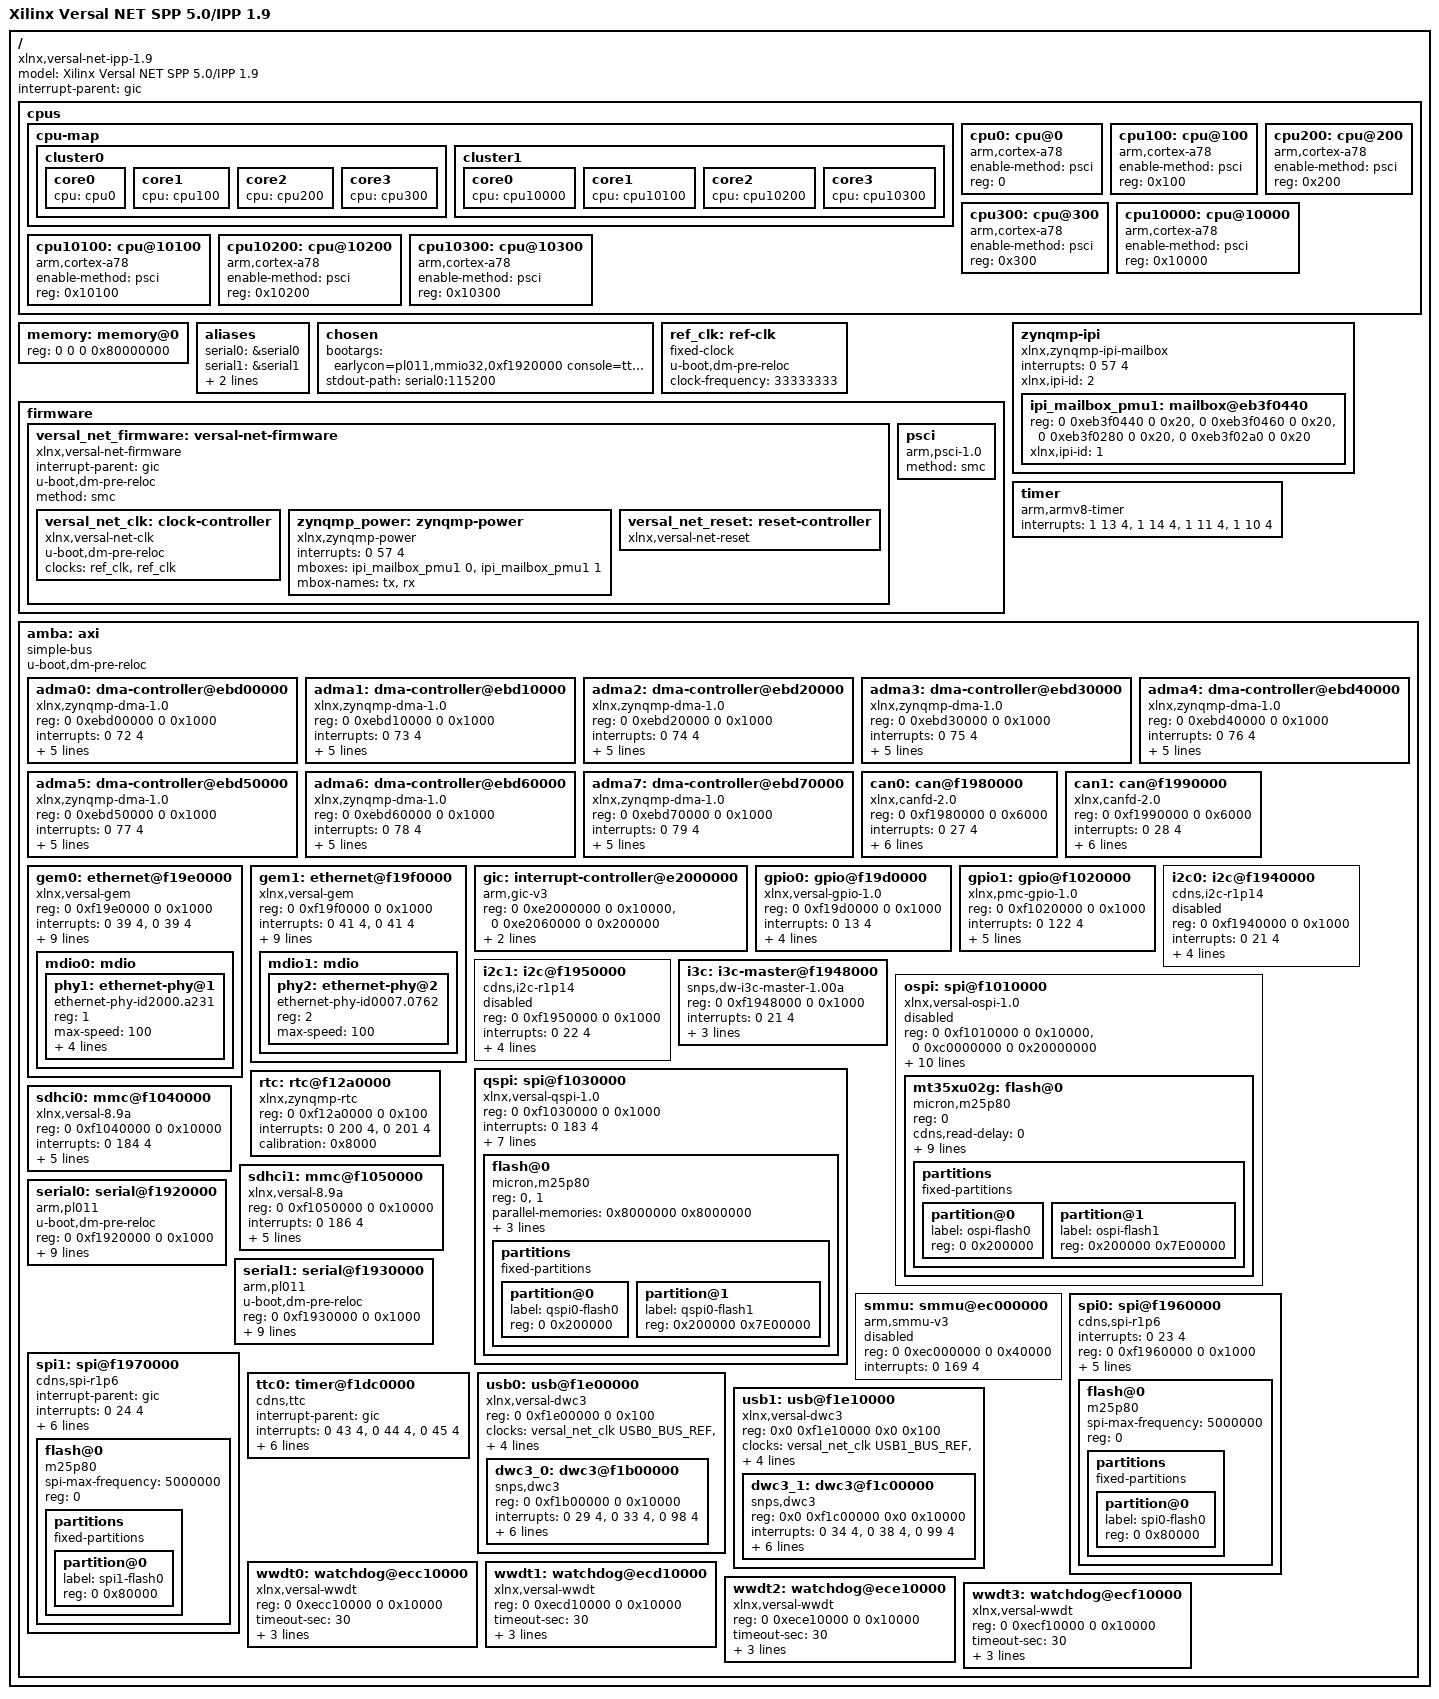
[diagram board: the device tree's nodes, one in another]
// SPDX-License-Identifier: GPL-2.0
/*
 * dts file for Xilinx Versal NET
 *
 * (C) Copyright 2021 - 2022, Xilinx, Inc.
 *
 * Michal Simek <michal.simek@amd.com>
 */

/dts-v1/;

#include <dt-bindings/gpio/gpio.h>
#include <dt-bindings/clock/xlnx-versal-net-clk.h>
#include <dt-bindings/power/xlnx-versal-net-power.h>
#include <dt-bindings/reset/xlnx-versal-net-resets.h>

/ {
	compatible = "xlnx,versal-net-ipp-1.9", "xlnx,versal-net-spp-5.0", "xlnx,versal-net-spp", "xlnx,versal-net";
	model = "Xilinx Versal NET SPP 5.0/IPP 1.9";
	#address-cells = <2>;
	#size-cells = <2>;
	interrupt-parent = <&gic>;

	cpus {
		#address-cells = <1>;
		#size-cells = <0>;
		cpu-map {
			cluster0 {
				core0 {
					cpu = <&cpu0>;
				};
				core1 {
					cpu = <&cpu100>;
				};
				core2 {
					cpu = <&cpu200>;
				};
				core3 {
					cpu = <&cpu300>;
				};
			};

			cluster1 {
				core0 {
					cpu = <&cpu10000>;
				};

				core1 {
					cpu = <&cpu10100>;
				};

				core2 {
					cpu = <&cpu10200>;
				};

				core3 {
					cpu = <&cpu10300>;
				};
			};
		};

		cpu0: cpu@0 {
			compatible = "arm,cortex-a78";
			device_type = "cpu";
			enable-method = "psci";
			reg = <0>;
		};
		cpu100: cpu@100 {
			compatible = "arm,cortex-a78";
			device_type = "cpu";
			enable-method = "psci";
			reg = <0x100>;
		};
		cpu200: cpu@200 {
			compatible = "arm,cortex-a78";
			device_type = "cpu";
			enable-method = "psci";
			reg = <0x200>;
		};
		cpu300: cpu@300 {
			compatible = "arm,cortex-a78";
			device_type = "cpu";
			enable-method = "psci";
			reg = <0x300>;
		};
		cpu10000: cpu@10000 {
			compatible = "arm,cortex-a78";
			device_type = "cpu";
			enable-method = "psci";
			reg = <0x10000>;
		};
		cpu10100: cpu@10100 {
			compatible = "arm,cortex-a78";
			device_type = "cpu";
			enable-method = "psci";
			reg = <0x10100>;
		};
		cpu10200: cpu@10200 {
			compatible = "arm,cortex-a78";
			device_type = "cpu";
			enable-method = "psci";
			reg = <0x10200>;
		};
		cpu10300: cpu@10300 {
			compatible = "arm,cortex-a78";
			device_type = "cpu";
			enable-method = "psci";
			reg = <0x10300>;
		};
	};

	memory: memory@0 {
		reg = <0 0 0 0x80000000>;
		device_type = "memory";
	};

	aliases {
		serial0 = &serial0;
		serial1 = &serial1;
		mmc0 = &sdhci0;
		mmc1 = &sdhci1;
	};

	chosen {
		bootargs = "earlycon=pl011,mmio32,0xf1920000 console=ttyAMA0,115200 spi-cadence-quadspi.read_timeout_ms=30 dw-i3c-master.scl_timing_quirk_spp=1";
		stdout-path = "serial0:115200";
	};

	ref_clk: ref-clk {
		compatible = "fixed-clock";
		u-boot,dm-pre-reloc;
		#clock-cells = <0>;
		clock-frequency = <33333333>;
	};

	firmware {
		versal_net_firmware: versal-net-firmware {
			compatible = "xlnx,versal-net-firmware";
			interrupt-parent = <&gic>;
			u-boot,dm-pre-reloc;
			method = "smc";
			#power-domain-cells = <0x01>;

			versal_net_clk: clock-controller {
				u-boot,dm-pre-reloc;
				#clock-cells = <1>;
				compatible = "xlnx,versal-net-clk";
				clocks = <&ref_clk>, <&ref_clk>;
				clock-names = "ref_clk", "pl_alt_ref_clk";
			};

			zynqmp_power: zynqmp-power {
				compatible = "xlnx,zynqmp-power";
				interrupts = <0 57 4>;
				mboxes = <&ipi_mailbox_pmu1 0>,
					<&ipi_mailbox_pmu1 1>;
				mbox-names = "tx", "rx";
			};

			versal_net_reset: reset-controller {
				compatible = "xlnx,versal-net-reset";
				#reset-cells = <1>;
			};
		};

		psci {
			compatible = "arm,psci-1.0";
			method = "smc";
		};
	};

	zynqmp-ipi {
		compatible = "xlnx,zynqmp-ipi-mailbox";
		interrupts = <0 57 4>;
		xlnx,ipi-id = <2>;
		#address-cells = <2>;
		#size-cells = <2>;
		ranges;

		ipi_mailbox_pmu1: mailbox@eb3f0440 {
			reg = <0 0xeb3f0440 0 0x20>,
			      <0 0xeb3f0460 0 0x20>,
			      <0 0xeb3f0280 0 0x20>,
			      <0 0xeb3f02a0 0 0x20>;
			reg-names = "local_request_region", "local_response_region",
				    "remote_request_region", "remote_response_region";
			#mbox-cells = <1>;
			xlnx,ipi-id = <1>;
		};
	};

	timer: timer {
		compatible = "arm,armv8-timer";
		interrupts = <1 13 4>, <1 14 4>, <1 11 4>, <1 10 4>; /* FIXME 3rd cell */
	};

	amba: axi {
		compatible = "simple-bus";
		u-boot,dm-pre-reloc;
		#address-cells = <2>;
		#size-cells = <2>;
		ranges;

		adma0: dma-controller@ebd00000 {
			compatible = "xlnx,zynqmp-dma-1.0";
			status = "okay";
			reg = <0 0xebd00000 0 0x1000>;
			interrupts = <0 72 4>;
			clock-names = "clk_main", "clk_apb";
			#dma-cells = <1>;
			xlnx,bus-width = <64>;
			clocks = <&versal_net_clk ADMA>, <&versal_net_clk LPD_LSBUS>;
			power-domains = <&versal_net_firmware PM_DEV_ADMA_0>;
		};

		adma1: dma-controller@ebd10000 {
			compatible = "xlnx,zynqmp-dma-1.0";
			status = "okay";
			reg = <0 0xebd10000 0 0x1000>;
			interrupts = <0 73 4>;
			clock-names = "clk_main", "clk_apb";
			#dma-cells = <1>;
			xlnx,bus-width = <64>;
			clocks = <&versal_net_clk ADMA>, <&versal_net_clk LPD_LSBUS>;
			power-domains = <&versal_net_firmware PM_DEV_ADMA_1>;
		};

		adma2: dma-controller@ebd20000 {
			compatible = "xlnx,zynqmp-dma-1.0";
			status = "okay";
			reg = <0 0xebd20000 0 0x1000>;
			interrupts = <0 74 4>;
			clock-names = "clk_main", "clk_apb";
			#dma-cells = <1>;
			xlnx,bus-width = <64>;
			clocks = <&versal_net_clk ADMA>, <&versal_net_clk LPD_LSBUS>;
			power-domains = <&versal_net_firmware PM_DEV_ADMA_2>;
		};

		adma3: dma-controller@ebd30000 {
			compatible = "xlnx,zynqmp-dma-1.0";
			status = "okay";
			reg = <0 0xebd30000 0 0x1000>;
			interrupts = <0 75 4>;
			clock-names = "clk_main", "clk_apb";
			#dma-cells = <1>;
			xlnx,bus-width = <64>;
			clocks = <&versal_net_clk ADMA>, <&versal_net_clk LPD_LSBUS>;
			power-domains = <&versal_net_firmware PM_DEV_ADMA_3>;
		};

		adma4: dma-controller@ebd40000 {
			compatible = "xlnx,zynqmp-dma-1.0";
			status = "okay";
			reg = <0 0xebd40000 0 0x1000>;
			interrupts = <0 76 4>;
			clock-names = "clk_main", "clk_apb";
			#dma-cells = <1>;
			xlnx,bus-width = <64>;
			clocks = <&versal_net_clk ADMA>, <&versal_net_clk LPD_LSBUS>;
			power-domains = <&versal_net_firmware PM_DEV_ADMA_4>;
		};

		adma5: dma-controller@ebd50000 {
			compatible = "xlnx,zynqmp-dma-1.0";
			status = "okay";
			reg = <0 0xebd50000 0 0x1000>;
			interrupts = <0 77 4>;
			clock-names = "clk_main", "clk_apb";
			#dma-cells = <1>;
			xlnx,bus-width = <64>;
			clocks = <&versal_net_clk ADMA>, <&versal_net_clk LPD_LSBUS>;
			power-domains = <&versal_net_firmware PM_DEV_ADMA_5>;
		};

		adma6: dma-controller@ebd60000 {
			compatible = "xlnx,zynqmp-dma-1.0";
			status = "okay";
			reg = <0 0xebd60000 0 0x1000>;
			interrupts = <0 78 4>;
			clock-names = "clk_main", "clk_apb";
			#dma-cells = <1>;
			xlnx,bus-width = <64>;
			clocks = <&versal_net_clk ADMA>, <&versal_net_clk LPD_LSBUS>;
			power-domains = <&versal_net_firmware PM_DEV_ADMA_6>;
		};

		adma7: dma-controller@ebd70000 {
			compatible = "xlnx,zynqmp-dma-1.0";
			status = "okay";
			reg = <0 0xebd70000 0 0x1000>;
			interrupts = <0 79 4>;
			clock-names = "clk_main", "clk_apb";
			#dma-cells = <1>;
			xlnx,bus-width = <64>;
			clocks = <&versal_net_clk ADMA>, <&versal_net_clk LPD_LSBUS>;
			power-domains = <&versal_net_firmware PM_DEV_ADMA_7>;
		};

		can0: can@f1980000 {
			compatible = "xlnx,canfd-2.0";
			status = "okay";
			reg = <0 0xf1980000 0 0x6000>;
			interrupts = <0 27 4>;
			clock-names = "can_clk", "s_axi_aclk";
			rx-fifo-depth = <64>;
			tx-mailbox-count = <32>;
			clocks = <&versal_net_clk CAN0_REF_2X>, <&versal_net_clk LPD_LSBUS>;
			power-domains = <&versal_net_firmware PM_DEV_CAN_FD_0>;
		};

		can1: can@f1990000 {
			compatible = "xlnx,canfd-2.0";
			status = "okay";
			reg = <0 0xf1990000 0 0x6000>;
			interrupts = <0 28 4>;
			clock-names = "can_clk", "s_axi_aclk";
			rx-fifo-depth = <64>;
			tx-mailbox-count = <32>;
			clocks = <&versal_net_clk CAN1_REF_2X>, <&versal_net_clk LPD_LSBUS>;
			power-domains = <&versal_net_firmware PM_DEV_CAN_FD_1>;
		};

		gem0: ethernet@f19e0000 {
			compatible = "xlnx,versal-gem", "cdns,gem";
			status = "okay";
			reg = <0 0xf19e0000 0 0x1000>;
			interrupts = <0 39 4>, <0 39 4>;
			clock-names = "pclk", "hclk", "tx_clk", "rx_clk", "tsu_clk";
			#address-cells = <1>;
			#size-cells = <0>;
			phy-handle = <&phy1>;
			phy-mode = "rgmii-id";
			clocks = <&versal_net_clk LPD_LSBUS>,
				 <&versal_net_clk GEM0_REF>, <&versal_net_clk GEM0_TX>,
				 <&versal_net_clk GEM0_RX>, <&versal_net_clk GEM_TSU>;
			power-domains = <&versal_net_firmware PM_DEV_GEM_0>;
			mdio0: mdio {
				#address-cells = <1>;
				#size-cells = <0>;
				phy1: ethernet-phy@1 {
					#phy-cells = <1>;
					compatible = "ethernet-phy-id2000.a231";
					reg = <1>;
					max-speed = <100>;
					ti,rx-internal-delay = <11>;
					ti,tx-internal-delay = <10>;
					ti,fifo-depth = <1>;
					ti,dp83867-rxctrl-strap-quirk;
				};
			};
		};

		gem1: ethernet@f19f0000 {
			compatible = "xlnx,versal-gem", "cdns,gem";
			status = "okay";
			reg = <0 0xf19f0000 0 0x1000>;
			interrupts = <0 41 4>, <0 41 4>;
			clock-names = "pclk", "hclk", "tx_clk", "rx_clk", "tsu_clk";
			#address-cells = <1>;
			#size-cells = <0>;
			phy-handle = <&phy2>;
			phy-mode = "rmii";
			clocks = <&versal_net_clk LPD_LSBUS>,
				 <&versal_net_clk GEM1_REF>, <&versal_net_clk GEM1_TX>,
				 <&versal_net_clk GEM1_RX>, <&versal_net_clk GEM_TSU>;
			power-domains = <&versal_net_firmware PM_DEV_GEM_1>;
			mdio1: mdio {
				#address-cells = <1>;
				#size-cells = <0>;

				phy2: ethernet-phy@2 {
					compatible = "ethernet-phy-id0007.0762"; /* Vitesse VSC8540 */
					reg = <2>;
					max-speed = <100>;
				};
			};
		};

		gic: interrupt-controller@e2000000 {
			compatible = "arm,gic-v3";
			#interrupt-cells = <3>;
			reg = <0 0xe2000000 0 0x10000>, <0 0xe2060000 0 0x200000>;
			interrupt-controller;
			interrupts = <1 9 4>;
		};

		gpio0: gpio@f19d0000 {
			compatible = "xlnx,versal-gpio-1.0";
			status = "okay";
			reg = <0 0xf19d0000 0 0x1000>;
			interrupts = <0 13 4>;
			#gpio-cells = <2>;
			gpio-controller;
			#interrupt-cells = <2>;
			interrupt-controller;
			clocks = <&versal_net_clk LPD_LSBUS>;
			power-domains = <&versal_net_firmware PM_DEV_GPIO>;
		};

		gpio1: gpio@f1020000 {
			compatible = "xlnx,pmc-gpio-1.0";
			status = "okay";
			reg = <0 0xf1020000 0 0x1000>;
			interrupts = <0 122 4>;
			#gpio-cells = <2>;
			gpio-controller;
			#interrupt-cells = <2>;
			interrupt-controller;
			clocks = <&versal_net_clk PMC_LSBUS_REF>;
			power-domains = <&versal_net_firmware PM_DEV_GPIO_PMC>;
		};

		i2c0: i2c@f1940000 {
			compatible = "cdns,i2c-r1p14";
			status = "disabled";
			reg = <0 0xf1940000 0 0x1000>;
			interrupts = <0 21 4>;
			clock-frequency = <400000>;
			#address-cells = <1>;
			#size-cells = <0>;
			clocks = <&versal_net_clk I3C0_REF>;
			power-domains = <&versal_net_firmware PM_DEV_I2C_0>;
		};

		i2c1: i2c@f1950000 {
			compatible = "cdns,i2c-r1p14";
			status = "disabled";
			reg = <0 0xf1950000 0 0x1000>;
			interrupts = <0 22 4>;
			clock-frequency = <400000>;
			#address-cells = <1>;
			#size-cells = <0>;
			clocks = <&versal_net_clk I3C1_REF>;
			power-domains = <&versal_net_firmware PM_DEV_I2C_1>;
		};

		i3c: i3c-master@f1948000 {
			compatible = "snps,dw-i3c-master-1.00a";
			status = "okay";
			reg = <0 0xf1948000 0 0x1000>;
			#address-cells = <1>;
			#size-cells = <0>;
			interrupts = <0 21 4>;
			clocks = <&versal_net_clk I2C_REF>;
			power-domains = <&versal_net_firmware PM_DEV_I2C_PMC>;
		};

		ospi: spi@f1010000 {
			compatible = "xlnx,versal-ospi-1.0", "cdns,qspi-nor";
			status = "disabled";
			reg = <0 0xf1010000 0 0x10000>, <0 0xc0000000 0 0x20000000>;
			interrupts = <0 182 4>;
			cdns,fifo-depth = <256>;
			cdns,fifo-width = <4>;
			cdns,is-dma = <1>;
			cdns,trigger-address = <0xc0000000>;
			is-dual = <0>;
			is-stacked = <0>;
			clocks = <&versal_net_clk OSPI_REF>;
			#address-cells = <1>;
			#size-cells = <0>;
			power-domains = <&versal_net_firmware PM_DEV_OSPI>;
			reset-gpios = <&gpio1 0xc GPIO_ACTIVE_HIGH>;

			mt35xu02g: flash@0 {
				compatible = "micron,m25p80", "jedec,spi-nor";
				reg = <0>;
				#address-cells = <1>;
				#size-cells = <1>;
				cdns,read-delay = <0>;
				cdns,tshsl-ns = <0>;
				cdns,tsd2d-ns = <0>;
				cdns,tchsh-ns = <1>;
				cdns,tslch-ns = <1>;
				spi-tx-bus-width = <8>;
				spi-rx-bus-width = <8>;
				spi-max-frequency = <5000000>;
				broken-flash-reset;
				no-wp;

				partitions {
					compatible = "fixed-partitions";
					#address-cells = <1>;
					#size-cells = <1>;

					partition@0 {
						label = "ospi-flash0";
						reg = <0 0x200000>;
					};
					partition@1 {
						label = "ospi-flash1";
						reg = <0x200000 0x7E00000>;
					};
				};
			};
		};

		qspi: spi@f1030000 {
			compatible = "xlnx,versal-qspi-1.0";
			status = "okay";
			reg = <0 0xf1030000 0 0x1000>;
			interrupts = <0 183 4>;
			clock-names = "ref_clk", "pclk";
			num-cs = <2>;
			is-dual = <1>;
			spi-rx-bus-width = <4>;
			spi-tx-bus-width = <4>;
			clocks = <&versal_net_clk QSPI_REF>, <&versal_net_clk LPD_LSBUS>;
			power-domains = <&versal_net_firmware PM_DEV_QSPI>;
			#address-cells = <1>;
			#size-cells = <0>;

			flash@0 {
				compatible = "micron,m25p80", "jedec,spi-nor";
				reg = <0>, <1>;
				parallel-memories = /bits/ 64 <0x8000000 0x8000000>; /* 128MB */
				#address-cells = <1>;
				#size-cells = <1>;
				spi-tx-bus-width = <1>;
				spi-rx-bus-width = <4>;
				spi-max-frequency = <10000000>;

				partitions {
					compatible = "fixed-partitions";
					#address-cells = <1>;
					#size-cells = <1>;

					partition@0 {
						label = "qspi0-flash0";
						reg = <0 0x200000>;
					};
					partition@1 {
						label = "qspi0-flash1";
						reg = <0x200000 0x7E00000>;
					};
				};
			};
		};

		rtc: rtc@f12a0000 {
			compatible = "xlnx,zynqmp-rtc";
			status = "okay";
			reg = <0 0xf12a0000 0 0x100>;
			interrupts = <0 200 4>, <0 201 4>;
			interrupt-names = "alarm", "sec";
			calibration = <0x8000>;
		};

		sdhci0: mmc@f1040000 {
			compatible = "xlnx,versal-8.9a", "arasan,sdhci-8.9a";
			status = "okay";
			reg = <0 0xf1040000 0 0x10000>;
			interrupts = <0 184 4>;
			clock-names = "clk_xin", "clk_ahb";
			no-1-8-v;
			clocks = <&versal_net_clk SDIO0_REF>, <&versal_net_clk LPD_LSBUS>;
			power-domains = <&versal_net_firmware PM_DEV_SDIO_0>;
		};

		sdhci1: mmc@f1050000 {
			compatible = "xlnx,versal-8.9a", "arasan,sdhci-8.9a";
			status = "okay";
			reg = <0 0xf1050000 0 0x10000>;
			interrupts = <0 186 4>;
			clock-names = "clk_xin", "clk_ahb";
			no-1-8-v;
			clocks = <&versal_net_clk SDIO1_REF>, <&versal_net_clk LPD_LSBUS>;
			power-domains = <&versal_net_firmware PM_DEV_SDIO_1>;
		};

		serial0: serial@f1920000 {
			u-boot,dm-pre-reloc;
			compatible = "arm,pl011", "arm,primecell";
			reg = <0 0xf1920000 0 0x1000>;
			interrupts = <0 25 4>;
			reg-io-width = <4>;
			clock-names = "uartclk", "apb_pclk";
			clocks = <&versal_net_clk UART0_REF>, <&versal_net_clk LPD_LSBUS>;
			power-domains = <&versal_net_firmware PM_DEV_UART_0>;
			clock = <1000000>;
			current-speed = <115200>;
			skip-init;
		};

		serial1: serial@f1930000 {
			u-boot,dm-pre-reloc;
			compatible = "arm,pl011", "arm,primecell";
			reg = <0 0xf1930000 0 0x1000>;
			interrupts = <0 26 4>;
			reg-io-width = <4>;
			clock-names = "uartclk", "apb_pclk";
			clocks = <&versal_net_clk UART1_REF>, <&versal_net_clk LPD_LSBUS>;
			power-domains = <&versal_net_firmware PM_DEV_UART_1>;
			clock = <1000000>;
			current-speed = <115200>;
			skip-init;
		};

		smmu: smmu@ec000000 {
			compatible = "arm,smmu-v3";
			status = "disabled";
			reg = <0 0xec000000 0 0x40000>;
			#iommu-cells = <1>;
			interrupt-names = "combined";
			interrupts = <0 169 4>;
		};

		spi0: spi@f1960000 {
			compatible = "cdns,spi-r1p6";
			status = "okay";
			interrupts = <0 23 4>;
			reg = <0 0xf1960000 0 0x1000>;
			clock-names = "ref_clk", "pclk";
			#address-cells = <1>;
			#size-cells = <0>;
			clocks = <&versal_net_clk SPI0_REF>, <&versal_net_clk LPD_LSBUS>;
			power-domains = <&versal_net_firmware PM_DEV_SPI_0>;
			num-cs = <1>;

			flash@0 {
				compatible = "m25p80";
				spi-max-frequency = <5000000>;
				reg = <0>;

				partitions {
					compatible = "fixed-partitions";
					#address-cells = <1>;
					#size-cells = <1>;
					partition@0 {
						label = "spi0-flash0";
						reg = <0 0x80000>;
					};
				};
			};
		};

		spi1: spi@f1970000 {
			compatible = "cdns,spi-r1p6";
			status = "okay";
			interrupt-parent = <&gic>;
			interrupts = <0 24 4>;
			reg = <0 0xf1970000 0 0x1000>;
			clock-names = "ref_clk", "pclk";
			#address-cells = <1>;
			#size-cells = <0>;
			clocks = <&versal_net_clk SPI1_REF>, <&versal_net_clk LPD_LSBUS>;
			power-domains = <&versal_net_firmware PM_DEV_SPI_1>;
			num-cs = <1>;

			flash@0 {
				compatible = "m25p80";
				spi-max-frequency = <5000000>;
				reg = <0>;

				partitions {
					compatible = "fixed-partitions";
					#address-cells = <1>;
					#size-cells = <1>;
					partition@0 {
						label = "spi1-flash0";
						reg = <0 0x80000>;
					};
				};
			};
		};

		ttc0: timer@f1dc0000 {
			compatible = "cdns,ttc";
			status = "okay";
			interrupt-parent = <&gic>;
			interrupts = <0 43 4>, <0 44 4>, <0 45 4>;
			timer-width = <32>;
			reg = <0x0 0xf1dc0000 0x0 0x1000>;
			clocks = <&versal_net_clk TTC0>, <&versal_net_clk LPD_LSBUS>;
			power-domains = <&versal_net_firmware PM_DEV_TTC_0>;
		};

		usb0: usb@f1e00000 {
			compatible = "xlnx,versal-dwc3";
			status = "okay";
			reg = <0 0xf1e00000 0 0x100>;
			clock-names = "bus_clk", "ref_clk";
			ranges;
			#address-cells = <2>;
			#size-cells = <2>;
			/* clocks = <&clk60>, <&clk60>; */
			clocks = <&versal_net_clk USB0_BUS_REF>, <&versal_net_clk USB0_BUS_REF>;
			power-domains = <&versal_net_firmware PM_DEV_USB_0>;
			resets = <&versal_net_reset VERSAL_RST_USB_0>;

			dwc3_0: dwc3@f1b00000  {
				compatible = "snps,dwc3";
				status = "okay";
				reg = <0 0xf1b00000 0 0x10000>;
				interrupt-names = "dwc_usb3","otg","usb-wakeup";
				interrupts = <0 29 4>, <0 33 4>, <0 98 4>;
				snps,dis_u2_susphy_quirk;
				snps,dis_u3_susphy_quirk;
				snps,quirk-frame-length-adjustment = <0x20>;
				dr_mode = "peripheral";
				maximum-speed = "high-speed";
				snps,usb3_lpm_capable;
				phy-names = "usb3-phy";
			};
		};

		usb1: usb@f1e10000 {
			compatible = "xlnx,versal-dwc3";
			status = "okay";
			reg = <0x0 0xf1e10000 0x0 0x100>;
			clock-names = "bus_clk", "ref_clk";
			ranges;
			#address-cells = <2>;
			#size-cells = <2>;
			clocks = <&versal_net_clk USB1_BUS_REF>, <&versal_net_clk USB1_BUS_REF>;
			power-domains = <&versal_net_firmware PM_DEV_USB_1>;
			resets = <&versal_net_reset VERSAL_RST_USB_1>;

			dwc3_1: dwc3@f1c00000  {
				compatible = "snps,dwc3";
				status = "okay";
				reg = <0x0 0xf1c00000 0x0 0x10000>;
				interrupt-names = "dwc_usb3","otg","usb-wakeup";
				interrupts = <0 34 4>, <0 38 4>, <0 99 4>;
				snps,dis_u2_susphy_quirk;
				snps,dis_u3_susphy_quirk;
				snps,quirk-frame-length-adjustment = <0x20>;
				dr_mode = "host";
				maximum-speed = "high-speed";
				snps,usb3_lpm_capable;
				phy-names = "usb3-phy";
			};
		};

		wwdt0: watchdog@ecc10000 {
			compatible = "xlnx,versal-wwdt";
			status = "okay";
			reg = <0 0xecc10000 0 0x10000>;
			timeout-sec = <30>;
			clocks = <&versal_net_clk FPD_WWDT>;
			power-domains = <&versal_net_firmware PM_DEV_FPD_SWDT_0>;
		};

		wwdt1: watchdog@ecd10000 {
			compatible = "xlnx,versal-wwdt";
			status = "okay";
			reg = <0 0xecd10000 0 0x10000>;
			timeout-sec = <30>;
			clocks = <&versal_net_clk FPD_WWDT>;
			power-domains = <&versal_net_firmware PM_DEV_FPD_SWDT_1>;
		};

		wwdt2: watchdog@ece10000 {
			compatible = "xlnx,versal-wwdt";
			status = "okay";
			reg = <0 0xece10000 0 0x10000>;
			timeout-sec = <30>;
			clocks = <&versal_net_clk FPD_WWDT>;
			power-domains = <&versal_net_firmware PM_DEV_FPD_SWDT_2>;
		};

		wwdt3: watchdog@ecf10000 {
			compatible = "xlnx,versal-wwdt";
			status = "okay";
			reg = <0 0xecf10000 0 0x10000>;
			timeout-sec = <30>;
			clocks = <&versal_net_clk FPD_WWDT>;
			power-domains = <&versal_net_firmware PM_DEV_FPD_SWDT_3>;
		};
	};
};
